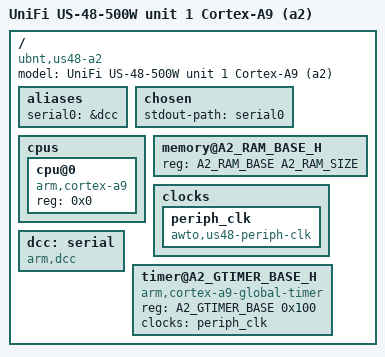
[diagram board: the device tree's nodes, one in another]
// SPDX-License-Identifier: GPL-2.0-or-later OR MIT
/*
 * a2 (unit 1 Cortex-A9) awto-uboot. Addresses come from hwdb via us48-a2-hwdb.h
 * (generated by scripts/build_uboot.py), never edited here. DCC console, no peripherals beyond the A9 block.
 */

/dts-v1/;

#include "us48-a2-hwdb.h"

/ {
	compatible = "ubnt,us48-a2", "brcm,hr2";
	model = "UniFi US-48-500W unit 1 Cortex-A9 (a2)";
	#address-cells = <1>;
	#size-cells = <1>;

	aliases {
		serial0 = &dcc;
	};

	chosen {
		stdout-path = "serial0";
	};

	cpus {
		#address-cells = <1>;
		#size-cells = <0>;

		cpu@0 {
			device_type = "cpu";
			compatible = "arm,cortex-a9";
			reg = <0x0>;
		};
	};

	/* carveout minus a2_shared (the last MiB is a1's: resource table, trace) */
	memory@A2_RAM_BASE_H {
		device_type = "memory";
		reg = <A2_RAM_BASE A2_RAM_SIZE>;
	};

	clocks {
		#address-cells = <1>;
		#size-cells = <1>;
		ranges;

		/* ARM/2 read from the ARM PLL regs (board.c) */
		periph_clk: periph_clk {
			#clock-cells = <0>;
			compatible = "awto,us48-periph-clk";
		};
	};

	dcc: serial {
		compatible = "arm,dcc";
	};

	timer@A2_GTIMER_BASE_H {
		compatible = "arm,cortex-a9-global-timer";
		reg = <A2_GTIMER_BASE 0x100>;
		clocks = <&periph_clk>;
	};
};
